# DISPC register map
Vendor: Texas Instruments
Registers are 32-bit, access per field, reset 0x0 unless marked. A register's access mark holds for its fields unless they carry their own. Offsets are as the file gives them; [hi:lo] are bit positions; {n}, {i} and the like mark numbered series; 'fields as' and 'values as' point back to an identical list.

## DISPC (part 5 of 7)
0x3A4 DISPC_VID3_ROW_INC rw reset 0x1 — The register configures the number of bytes to increment at the end of the row for the buffer associated with the video window 3. Shadow register, updated on VFP start period of primary LCD or VFP start period of the secondary LCD or VFP start period of the third LCD or EVSYNC or when.GOWB is set to 1 by software and current WB frame is finished (no more data in the write-back pipeline). The synchronization event is defined based on the output using the pipeline: primary LCD, secondary LCD, third LCD, TV output or write-back to the memory
  [31:0] ROWINC — Number of bytes to increment at the end of the row Encoded signed value (from 21 to 2) to specify the number of bytes to increment at the end of the row in the video buffer. The value 0 is invalid. The value 1 means next pixel. The value 1 + n * bpp means increment of n pixels. The value 1 (n + 1) * bpp means decrement of n pixels.
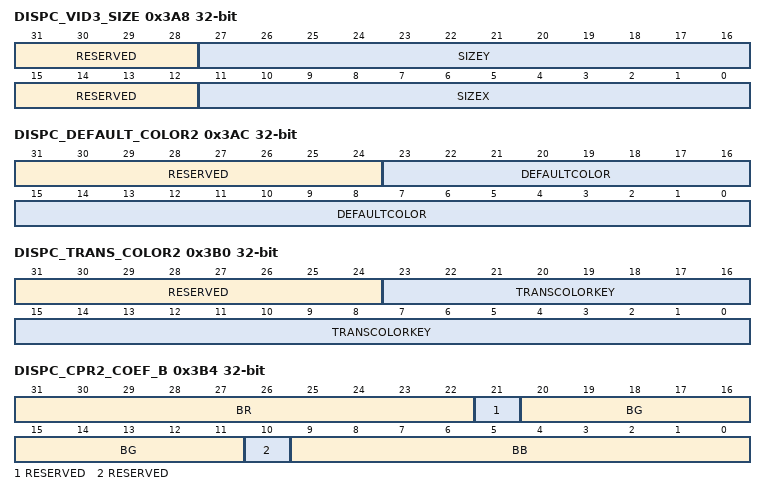
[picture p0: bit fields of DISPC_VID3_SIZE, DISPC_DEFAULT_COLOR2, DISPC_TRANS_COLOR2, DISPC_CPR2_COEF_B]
0x3A8 DISPC_VID3_SIZE — The register configures the size of the video window 3. Shadow register, updated on VFP start period of primary LCD or VFP start period of the secondary LCD or VFP start period of the third LCD or EVSYNC or when.GOWB is set to 1 by software and current WB frame is finished (no more data in the write-back pipeline). The synchronization event is defined based on the output using the pipeline: primary LCD, secondary LCD, third LCD, TV output or write-back to the memory
  [31:28] RESERVED ro — Write 0s for future compatibility. Reads return 0.
  [27:16] SIZEY rw — Number of lines of the video 3 Encoded value (from 1 to 4096) to specify the number of lines of the video window 3. Program to value minus 1.
  [15:12] RESERVED ro — Write 0s for future compatibility. Reads return 0.
  [11:0] SIZEX rw — Number of pixels of the video window 3 Encoded value (from 1 to 4096) to specify the number of pixels of the video window 3. Program to value minus 1.
0x3AC DISPC_DEFAULT_COLOR2 — The control register allows to configure the default solid background color for the secondary LCD Shadow register, updated on VFP start period of secondary LCD
  [31:24] RESERVED ro — Write 0s for future compatibility. Reads return 0.
  [23:0] DEFAULTCOLOR rw — 24-bit RGB color value to specify the default solid color to display when there is no data from the overlays.
0x3B0 DISPC_TRANS_COLOR2 — The register sets the transparency color value for the video/graphics overlays for the secondary LCD output. Shadow register, updated on VFP start period of the secondary LCD
  [31:24] RESERVED ro — Write 0s for future compatibility. Reads return 0.
  [23:0] TRANSCOLORKEY rw — Transparency Color Key Value in RGB format [0] BITMAP 1 (CLUT), [23,1] set to 0s [1:0] BITMAP 2 (CLUT), [23,2] set to 0s [3:0] BITMAP 4 (CLUT), [23,4] set to 0s [7:0] BITMAP 8 (CLUT), [23,8] set to 0s [11:0] RGB 12, [23,12] set to 0s [15:0] RGB 16, [23,16] set to 0s [23:0] RGB 24
0x3B4 DISPC_CPR2_COEF_B — The register configures the color phase rotation matrix coefficients for the Blue component. It is used for the secondary LCD output. Shadow register, updated on VFP start period of secondary LCD
  [31:22] BR rw — BR coefficient encoded signed value (from –512 to 511).
  [21] RESERVED ro — Write 0s for future compatibility. Reads return 0.
  [20:11] BG rw — BG coefficient encoded signed value (from –512 to 511).
  [10] RESERVED ro — Write 0s for future compatibility. Reads return 0.
  [9:0] BB rw — BB coefficient encoded signed value (from –512 to 511).
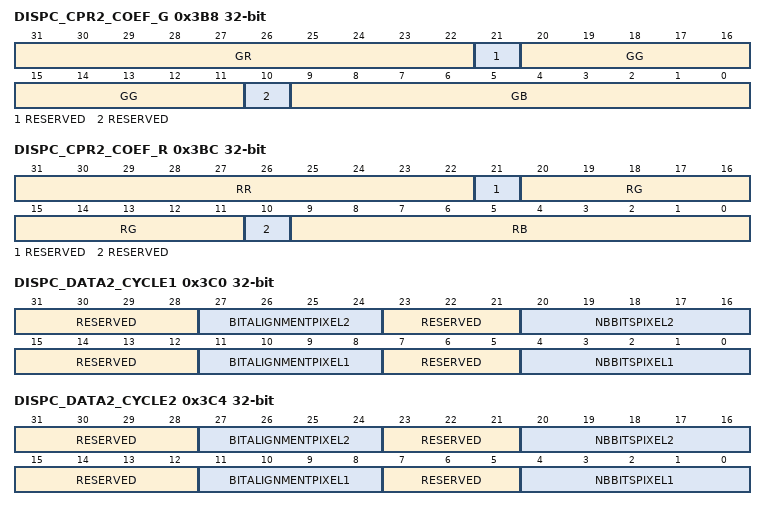
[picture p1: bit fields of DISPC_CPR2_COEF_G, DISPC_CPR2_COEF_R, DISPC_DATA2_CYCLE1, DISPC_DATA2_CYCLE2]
0x3B8 DISPC_CPR2_COEF_G — The register configures the color phase rotation matrix coefficients for the Green component. It is used for the secondary LCD output. Shadow register, updated on VFP start period of secondary LCD
  [31:22] GR rw — GR coefficient encoded signed value (from –512 to 511).
  [21] RESERVED ro — Write 0s for future compatibility. Reads return 0.
  [20:11] GG rw — GG coefficient encoded signed value (from –512 to 511).
  [10] RESERVED ro — Write 0s for future compatibility. Reads return 0.
  [9:0] GB rw — GB coefficient encoded signed value (from –512 to 511).
0x3BC DISPC_CPR2_COEF_R — The register configures the color phase rotation matrix coefficients for the Red component. Shadow register, updated on VFP start period of secondary LCD
  [31:22] RR rw — RR coefficient encoded signed value (from –512 to 511).
  [21] RESERVED ro — Write 0s for future compatibility. Reads return 0.
  [20:11] RG rw — RG coefficient encoded signed value (from –512 to 511).
  [10] RESERVED ro — Write 0s for future compatibility. Reads return 0.
  [9:0] RB rw — RB coefficient encoded signed value (from –512 to 511).
0x3C0 DISPC_DATA2_CYCLE1 — The control register configures the output data format for 1st cycle. Shadow register, updated on VFP start period of secondary LCD
  [31:28] RESERVED ro — Write 0s for future compatibility. Reads return 0.
  [27:24] BITALIGNMENTPIXEL2 rw — Bit alignment. Alignment of the bits from pixel 2 on the output interface
  [23:21] RESERVED ro — Write 0s for future compatibility. Reads return 0.
  [20:16] NBBITSPIXEL2 rw — Number of bits Number of bits from the pixel 2 (value from 0 to 16 bits). The values from 17 to 31 are invalid.
  [15:12] RESERVED ro — Write 0s for future compatibility. Reads return 0.
  [11:8] BITALIGNMENTPIXEL1 rw — Bit alignment. Alignment of the bits from pixel 1 on the output interface
  [7:5] RESERVED ro — Write 0s for future compatibility. Reads return 0.
  [4:0] NBBITSPIXEL1 rw — Number of bits Number of bits from the pixel 1 (value from 0 to 16 bits). The values from 17 to 31 are invalid.
0x3C4 DISPC_DATA2_CYCLE2 — The control register configures the output data format for 2nd cycle. Shadow register, updated on VFP start period of secondary LCD
  [31:28] RESERVED ro — Write 0s for future compatibility Reads return 0.
  [27:24] BITALIGNMENTPIXEL2 rw — Bit alignment. Alignment of the bits from pixel 2 on the output interface
  [23:21] RESERVED ro — Write 0s for future compatibility Reads return 0.
  [20:16] NBBITSPIXEL2 rw — Number of bits Number of bits from the pixel 2 (value from 0 to 16 bits). The values from 17 to 31 are invalid.
  [15:12] RESERVED ro — Write 0s for future compatibility Reads return 0.
  [11:8] BITALIGNMENTPIXEL1 rw — Bit alignment. Alignment of the bits from pixel 1 on the output interface
  [7:5] RESERVED ro — Write 0s for future compatibility Reads return 0.
  [4:0] NBBITSPIXEL1 rw — Number of bits Number of bits from the pixel 1 (value from 0 to 16 bits). The values from 17 to 31 are invalid.
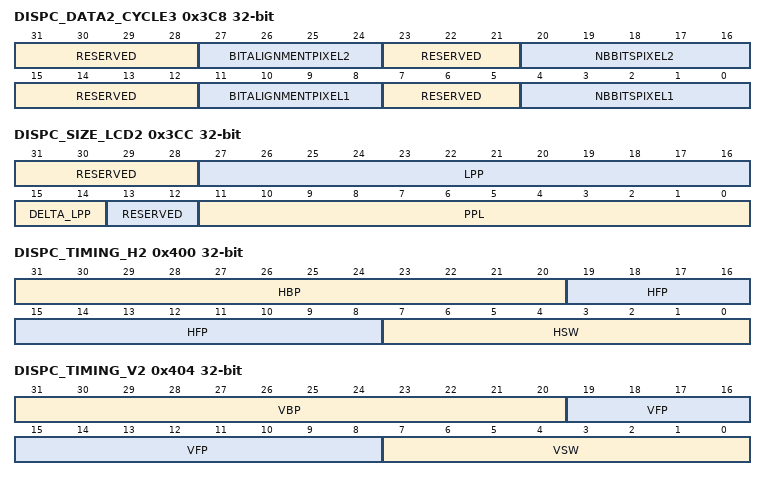
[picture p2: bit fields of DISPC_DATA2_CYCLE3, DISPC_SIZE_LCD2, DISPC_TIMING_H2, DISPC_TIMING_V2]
0x3C8 DISPC_DATA2_CYCLE3 — The control register configures the output data format for 3rd cycle. Shadow register, updated on VFP start period of secondary LCD
  fields as DISPC_DATA2_CYCLE2
0x3CC DISPC_SIZE_LCD2 — The register configures the panel size (horizontal and vertical). It is used for the secondary LCD output. Shadow register, updated on VFP start period of secondary LCD. A delta value is used to indicate if the odd field has same vertical size as the even field or +/- one line.
  [31:28] RESERVED ro — Write 0s for future compatibility. Reads return 0.
  [27:16] LPP rw — Lines per panel encoded value (from 1 to 4096) to specify the number of lines per panel (program to value minus 1).
  [15:14] DELTA_LPP rw — Indicates the delta size value of the odd field compared to the even field
    0=same size; 1=PlusOne (odd size = even size +1); 2=MinusOne (Odd size = even size –1)
  [13:12] RESERVED ro — Write 0s for future compatibility. Reads return 0.
  [11:0] PPL rw — Pixels per line encoded value (from 1 to 4096) to specify the number of pixels contains within each line on the display (program to value minus 1). In STALL mode, any value is valid. In non STALL mode, only values multiple of 8 pixels are valid.
0x400 DISPC_TIMING_H2 rw — The register configures the timing logic for the HSYNC signal. It is used for the secondary LCD output. Shadow register, updated on VFP start period of secondary LCD
  [31:20] HBP — Horizontal back porch. Encoded value (from 1 to 4096) to specify the number of pixel clock periods to add to the beginning of a line transmission before the first set of pixels is output to the display (program to value minus 1).
  [19:8] HFP — Horizontal front porch. Encoded value (from 1 to 4096) to specify the number of pixel clock periods to add to the end of a line transmission before line clock is asserted (program to value minus 1).
  [7:0] HSW — Horizontal synchronization pulse width encoded value (from 1 to 256) to specify the number of pixel clock periods to pulse the line clock at the end of each line (program to value minus 1).
0x404 DISPC_TIMING_V2 rw — The register configures the timing logic for the VSYNC signal. It is used for the secondary LCD output. Shadow register, updated on VFP start period of secondary LCD
  [31:20] VBP — Vertical back porch encoded value (from 0 to 4095) to specify the number of line clock periods to add to the beginning of a frame before the first set of pixels is output to the display.
  [19:8] VFP — Vertical front porch encoded value (from 0 to 4095) to specify the number of line clock periods to add to the end of each frame.
  [7:0] VSW — Vertical synchronization pulse width In active mode, encoded value (from 1 to 256) to specify the number of line clock periods (program to value minus 1) to pulse the frame clock (VSYNC) pin at the end of each frame after the end of frame wait (VFP) period elapses. Frame clock uses as VSYNC signal in active mode.
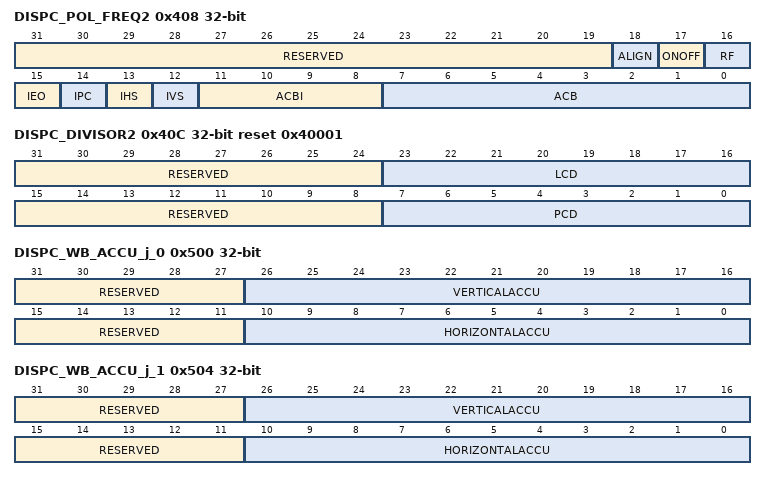
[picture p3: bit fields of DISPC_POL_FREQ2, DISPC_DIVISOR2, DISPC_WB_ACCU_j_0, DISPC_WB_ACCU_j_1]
0x408 DISPC_POL_FREQ2 — The register configures the signal configuration. It is used for the secondary LCD output. Shadow register, updated on VFP start period of secondary LCD
  [31:19] RESERVED ro — Write 0s for future compatibility. Reads return 0.
  [18] ALIGN rw — Defines the alignment between HSYNC and VSYNC assertion.
    0=notAligned (VSYNC and HSYNC are not aligned.); 1=Aligned (VSYNC and HSYNC assertions are aligned.)
  [17] ONOFF rw — HSYNC/VSYNC Pixel clock Control On/Off
    0=DOpEdPCk (HSYNC and VSYNC are driven on opposite edges of pixel clock than pixel data.); 1=DBit16 (HSYNC and VSYNC are driven according to bit 16.)
  [16] RF rw — Program HSYNC/VSYNC Rise or Fall
    0=DFEdPCk (HSYNC and VSYNC are driven on falling edge of pixel clock (if bit 17 set to 1).); 1=DRiEdPCk (HSYNC and VSYNC are driven on rising edge of pixel clock (if bit 17 set to 1).)
  [15] IEO rw — Invert output enable
    0=ACBaHigh (Ac-bias is active high (active display mode).); 1=ACBaLow (Ac-bias is active low (active display mode).)
  [14] IPC rw — Invert pixel clock
    0=DrPCk (Data is driven on the LCD data lines on the rising-edge of the pixel clock.); 1=DfPCk (Data is driven on the LCD data lines on the falling-edge of the pixel clock.)
  [13] IHS rw — Invert HSYNC
    0=LCkpinAh (Line clock pin is active high and inactive low.); 1=LCkpinAl (Line clock pin is active low and inactive high.)
  [12] IVS rw — Invert VSYNC
    0=FCkpinAh (Frame clock pin is active high and inactive low.); 1=FCkpinAl (Frame clock pin is active low and inactive high.)
  [11:8] ACBI rw — AC Bias Pin transitions per interrupt Value (from 0 to 15) used to specify the number of AC Bias pin transitions
  [7:0] ACB rw — AC Bias Pin Frequency Value (from 0 to 255) used to specify the number of line clocks to count before transitioning the AC Bias pin. This pin is used to periodically invert the polarity of the power supply to prevent DC charge build-up within the display.
0x40C DISPC_DIVISOR2 reset 0x40001 — The register configures the divisors. It is used for the secondary LCD output. Shadow register, updated on VFP start period of secondary LCD
  [31:24] RESERVED ro — Write 0s for future compatibility. Reads return 0.
  [23:16] LCD rw — Display controller logic clock divisor value (from 1 to 255) to specify the intermediate pixel clock frequency based on the LCD2_CLK. The value 0 is invalid.
  [15:8] RESERVED ro — Write 0s for future compatibility. Reads return 0.
  [7:0] PCD rw — Pixel clock divisor value (from 1 to 255) to specify the frequency of the pixel clock based on the LCD2_CLK divided byDISPC_DIVISOR2.LCD value. The value 0 is invalid.
0x500 DISPC_WB_ACCU_j_0 — The register configures the resize accumulator init values for horizontal and vertical up/downsampling of the write back pipeline (DISPC_WB_ACCU_0 and DISPC_WB_ACCU_1 for ping-pong mechanism with external trigger, based on the field polarity). It is used for ARGB and Y setting. Shadow register, updated when.GOWB is set to 1 by software and current WB frame is finished (no more data in the write-back pipeline) when the WB pipeline is directly connected to one of the pipelines (graphics or video), otherwise updated on VFP start period of primary LCD or VFP start period of secondary LCD or VFP start period of the third LCD or EVSYNC depending on which overlay output is selected as an input to the WB pipeline
  [31:27] RESERVED ro — Write 0s for future compatibility. Reads return 0.
  [26:16] VERTICALACCU rw — Vertical initialization accumulator value Encoded value (from –1024 to 1023).
  [15:11] RESERVED ro — Write 0s for future compatibility. Reads return 0.
  [10:0] HORIZONTALACCU rw — Horizontal initialization accumulator value encoded value (from –1024 to 1023).
0x504 DISPC_WB_ACCU_j_1 — The register configures the resize accumulator init values for horizontal and vertical up/downsampling of the write back pipeline (DISPC_WB_ACCU_0 and DISPC_WB_ACCU_1 for ping-pong mechanism with external trigger, based on the field polarity). It is used for ARGB and Y setting. Shadow register, updated when.GOWB is set to 1 by software and current WB frame is finished (no more data in the write-back pipeline) when the WB pipeline is directly connected to one of the pipelines (graphics or video), otherwise updated on VFP start period of primary LCD or VFP start period of secondary LCD or VFP start period of the third LCD or EVSYNC depending on which overlay output is selected as an input to the WB pipeline
  fields as DISPC_WB_ACCU_j_0
0x508 DISPC_WB_BA_j_0 rw — The register configures the base address of the WB buffer (DISPC_WB_BA_0 and DISPC_WB_BA_1 for ping-pong mechanism with external trigger, based on the field polarity otherwise only DISPC_WB_BA_0 is used). Shadow register, updated when.GOWB is set to 1 by software and current WB frame is finished (no more data in the write-back pipeline) when the WB pipeline is directly connected to one of the pipelines (graphics or video), otherwise updated on VFP start period of primary LCD or VFP start period of secondary LCD or VFP start period of the third LCD or EVSYNC depending on which overlay output is selected as an input to the WB pipeline
  [31:0] BA — Write-back base address Base address of the WB buffer (aligned on pixel size boundary except in case of RGB24 packed format, 4-pixel alignment is required; in case of YUV4:2:2, 2-pixel alignment is required, and YUV4:2;0, byte alignment is supported)). It case of YUV4:2:0 format, it indicates the base address of the Y buffer. When the TILER is addressed, the bits: [28:27] = 0x0 for 8-bit tiled [28:27] = 0x1 for 16-bit tiled [28:27] = 0x2 for 32-bit tiled [28:27] = 0x3 for page mode [31:29] = 0x0 for 0-degree view [31:29] = 0x1 for 180-degree view + mirroring [31:29] = 0x2 for 0-degree view + mirroring [31:29] = 0x3 for 180-degree view [31:29] = 0x4 for 270-degree view + mirroring [31:29] = 0x5 for 270-degree view [31:29] = 0x6 for 90-degree view [31:29] = 0x7 for 90-degree view + mirroring Otherwise the bits indicated the corresponding bit address to access the SDRAM.
0x50C DISPC_WB_BA_j_1 rw — The register configures the base address of the WB buffer (DISPC_WB_BA_0 and DISPC_WB_BA_1 for ping-pong mechanism with external trigger, based on the field polarity otherwise only DISPC_WB_BA_0 is used). Shadow register, updated when.GOWB is set to 1 by software and current WB frame is finished (no more data in the write-back pipeline) when the WB pipeline is directly connected to one of the pipelines (graphics or video), otherwise updated on VFP start period of primary LCD or VFP start period of secondary LCD or VFP start period of the third LCD or EVSYNC depending on which overlay output is selected as an input to the WB pipeline
  fields as DISPC_WB_BA_j_0
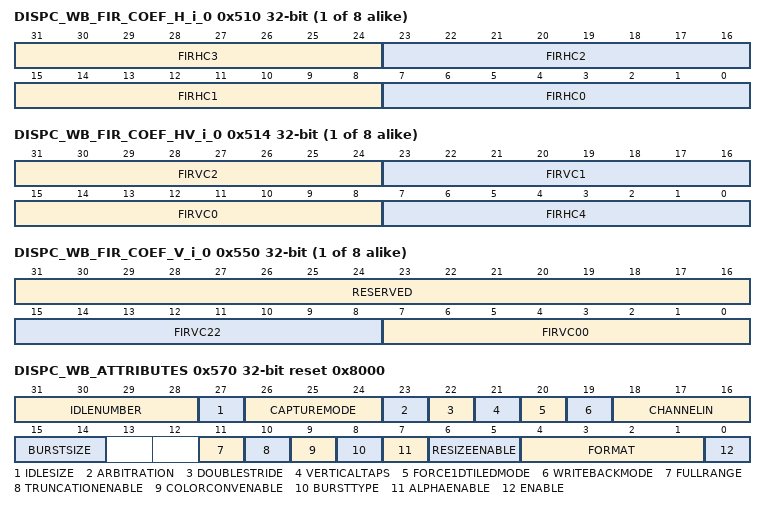
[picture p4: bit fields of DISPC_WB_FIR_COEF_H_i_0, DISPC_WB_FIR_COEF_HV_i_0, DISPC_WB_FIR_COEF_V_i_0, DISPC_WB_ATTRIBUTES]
{0x510+8i} DISPC_WB_FIR_COEF_H_i_{i} rw (i=0..7) — The bank of registers configure the up/down-scaling coefficients for the horizontal resize of the video picture associated with the write back pipeline for the phases from 0 to 7. It is used for ARGB and Y setting. Shadow register, updated when.GOWB is set to 1 by software and current WB frame is finished (no more data in the write-back pipeline) when the WB pipeline is directly connected to one of the pipelines (graphics or video), otherwise updated on VFP start period of primary LCD or VFP start period of secondary LCD or VFP start period of the third LCD or EVSYNC depending on which overlay output is selected as an input to the WB pipeline
  [31:24] FIRHC3 — Signed coefficient C3 for the horizontal up/down-scaling with the phase n
  [23:16] FIRHC2 — Unsigned coefficient C2 for the horizontal up/down-scaling with the phase n
  [15:8] FIRHC1 — Signed coefficient C1 for the horizontal up/down-scaling with the phase n
  [7:0] FIRHC0 — Signed coefficient C0 for the horizontal up/down-scaling with the phase n
{0x514+8i} DISPC_WB_FIR_COEF_HV_i_{i} rw (i=0..7) — The bank of registers configure the down/up/down-scaling coefficients for the vertical and horizontal resize of the video picture associated with the write back pipeline for the phases from 0 to 7. It is used for ARGB and Y setting. Shadow register, updated when.GOWB is set to 1 by software and current WB frame is finished (no more data in the write-back pipeline) when the WB pipeline is directly connected to one of the pipelines (graphics or video), otherwise updated on VFP start period of primary LCD or VFP start period of secondary LCD or VFP start period of the third LCD or EVSYNC depending on which overlay output is selected as an input to the WB pipeline
  [31:24] FIRVC2 — Signed coefficient C2 for the vertical up/down-scaling with the phase n
  [23:16] FIRVC1 — Unsigned coefficient C1 for the vertical up/down-scaling with the phase n
  [15:8] FIRVC0 — Signed coefficient C0 for the vertical up/down-scaling with the phase n
  [7:0] FIRHC4 — Signed coefficient C4 for the horizontal up/down-scaling with the phase n
{0x550+4i} DISPC_WB_FIR_COEF_V_i_{i} (i=0..7) — The bank of registers configure the down/up/down-scaling coefficients for the vertical resize of the video picture associated with the write back pipeline for the phases from 0 to 7. It is used for ARGB and Y setting. Shadow register, updated on VFP start period of primary LCD or VFP start period of the secondary LCD or VFP start period of the third LCD or EVSYNC or when.GOWB is set to 1 by software and current WB frame is finished (no more data in the write-back pipeline). The synchronization event is defined based on the output using the pipeline: primary LCD, secondary LCD, third LCD, TV output or write-back to the memory
  [31:16] RESERVED ro — Write 0s for future compatibility. Reads return 0.
  [15:8] FIRVC22 rw — Signed coefficient C22 for the vertical up/down-scaling with the phase n
  [7:0] FIRVC00 rw — Signed coefficient C00 for the vertical up/down-scaling with the phase n
0x570 DISPC_WB_ATTRIBUTES rw reset 0x8000 — The register configures the attributes of the viwrite back pipeline. Shadow register, updated when.GOWB is set to 1 by software and current WB frame is finished (no more data in the write-back pipeline) when the WB pipeline is directly connected to one of the pipelines (graphics or video), otherwise updated on VFP start period of primary LCD or VFP start period of secondary LCD or VFP start period of the third LCD or EVSYNC depending on which overlay output is selected as an input to the WB pipeline
  [31:28] IDLENUMBER — Determines the number of idles between requests on the L3_MAIN interconnect. It is only used when the write-back pipeline does data transfer from memory to memory. When the output of an overlay is stored in memory through the write-back pipeline in capture mode, the bit field IDLENUMBER is ignored since a timing generator is used to time the transfer. The number of IDLE cycles is IDLENUMBER (from 0 to 15) if IDLESIZE = 0. The number of IDLE cycles is IDLENUMBERx8 (from 0 to 120) if IDLESIZE = 1 and BURSTSIZE = 2. The number of IDLE cycles is IDLENUMBERx4 (from 0 to 60) if IDLESIZE = 1 and BURSTSIZE = 1. The number of IDLE cycles is IDLENUMBERx2 (from 0 to 30) if IDLESIZE = 1 and BURSTSIZE = 0.
  [27] IDLESIZE — Determines if the IDLENUMBER corresponds to a number of bursts or singles.
    0=IdleSingle (The number of idles between requests is defined by IDLENUMBER as number of cycles.); 1=IdleBurst (The number of idles between requests is defined by IDLENUMBER multiplied by burst size as number of cycles.)
  [26:24] CAPTUREMODE — Defines the frame rate capture.
    6=Only1_6 (Only one out of six frames is captured. The first one is captured then the second one is skipped and so on.); 1=Only1 (Only one frame is captured.); 7=Only1_7 (Only one out of seven frames is captured. The first one is captured then the second one is skipped and so on.); 0=All (All frames are captures until the write-back channel is disabled or there is no more data generated by the overlay or the pipeline attached to the write-back channel.); 2=Only1_2 (Only one out of two frames is captured. The first one is captured, and then the second one is skipped, and so on.); 4=Only1_4 (Only one out of four frames is captured. The first one is captured, and then the second one is skipped, and so on.); 5=Only1_5 (Only one out of five frames is captured. The first one is captured, and then the second one is skipped, and so on.); 3=Only1_3 (Only one out of three frames is captured. The first one is captured, and then the second one is skipped, and so on.)
  [23] ARBITRATION — Determines the priority of the write-back pipeline. The write-back pipeline is one of the high priority pipeline. The arbitration gives always the priority first to the high priority pipelines using round-robin between them. When there is only normal priority pipelines sending requests, the round-robin applies between them.
    0=NormalPrio (The write-back pipeline is one of the normal priority pipeline.); 1=HighPrio (The write-back pipeline is one of the high priority pipeline.)
  [22] DOUBLESTRIDE — Determines if the stride for CbCr buffer is the 1x or 2x of the Y buffer stride. It is only used in case of YUV4:2:0.
    0=Initial (The CbCr stride value is equal to the Y stride.); 1=Double (The CbCr stride value is double to the Y stride.)
  [21] VERTICALTAPS — Video Vertical Resize Tap Number
    0=taps3 (3 taps are used for the vertical filtering logic. The 2 other taps are not used.); 1=taps5 (5 taps are used for the vertical filtering logic.)
  [20] FORCE1DTILEDMODE — Force TILED regions access to 1D or 2D.
    0=TiledRegions2DAccess (2D accesses for tiled regions); 1=TiledRegions1DAccess (1D accesses for tiled regions)
  [19] WRITEBACKMODE — When connected to the overlay output of a channel the write back can operate as a simple transfer from memory to memory (composition engine) or as a capture channel. 0x0: Capture mode (default mode) 0x1: Memory-to-memory mode
  [18:16] CHANNELIN — Video Channel In configuration WR: immediate
    6=Vid3 (Video3 pipeline output); 1=LCD2 (Secondary LCD output); 0=LCD1 (Primary LCD overlay output); 2=TV (TV overlay output); 4=Vid1 (Video1 pipeline output); 5=Vid2 (Video2 pipeline output); 3=Gfx (Graphics pipeline output); 7=LCD3 (Third LCD output)
  [15:14] BURSTSIZE — Write-back DMA Burst Size
    0=Burst2x128b (2 × 128-bit bursts); 1=Burst4x128b (4 × 128-bit bursts); 2=Burst8x128b (8 × 128-bit bursts)
  [11] FULLRANGE — Color Space Conversion full range setting.
    0=Limrange (Limited range selected: 16 subtracted from Y before color space conversion); 1=Full range selected: Y is not modified before the color space conversion
  [10] TRUNCATIONENABLE — It applies only when the input format to the write-back pipeline from the overlay or directly from one of the pipelines is ARGB32. If the format is one of the YUV supported formats, the bit field is ignored.
    0=WBTruncDis (Disable truncation logic); 1=WBTruncEnb (Enable truncation logic from ARGB32 to the pixel format defined in the field FORMAT.)
  [9] COLORCONVENABLE — Enable the color space conversion. The hardware does not enable/disable the conversion based on the pixel format. The bit field shall be reset when the format is not YUV.
    0=ColSpCDis (Disable Color Space Conversion RGB to YUV); 1=ColSpCEnb (Enable Color Space Conversion RGB to YUV)
  [8] BURSTTYPE — The type of burst can be INCR (incremental) or BLCK (2D block). The 2D block is required when the TILER is targeted by the DMA engine.
    0=1D_burst (INC burst type is used.); 1=2D_burst (2D block burst type is used.)
  [7] ALPHAENABLE — Premultiplied alpha enable Read 0x1: Enabled Read 0x0: Disabled. This bit also disable the logic present in the associated channel out that compute the alpha component sent to the WB pipe. When the WB is configured to copy back one of the output channels (output of overlay), the following configurations are available: 0x1: The WB pipe copies back to memory the premultiplied alpha calculated through the overlay. 0x0: The alpha value is not written back.
  [6:5] RESIZEENABLE
    0=ReSizeProc (Disable the resize processing); 1=HReSize (Enable the horizontal resize processing); 3=HVReSize (Enable both horizontal and vertical resize processing); 2=VReSize (Enable the vertical resize processing)
  [4:1] FORMAT — Write-back format. It defines the pixel format when storing the write-back picture into memory.
    6=RGB16 (RGB16-565); 1=RGBx12 (RGB12x-4444); 10=YUV2 (YUV2 4:2:2 co-sited); 7=ARGB16_1 (ARGB16-1555); 13=RGBA32 (RGBA32-8888); 0=NV12 (NV12 4:2:0 2 buffers (Y + UV)); 2=RGBA12 (RGBA12-4444); 8=xRGB24-8888 (32-bit container); 9=RGB24 (RGB24-888 (24-bit container)); 11=UYVY (UYVY 4:2:2 co-sited); 5=ARGB16 (ARGB16-4444); 15=xRGB15-1555; 12=ARGB32 (ARGB32-8888); 4=xRGB12-4444; 3=BGRA32 (BGRA32-8888); 14=xRGB12 (RGBx24-8888 (24-bit RGB aligned on MSB of the 32-bit container))
  [0] ENABLE — Write-back enable. wr: immediate
    0=WBDis (Write-back disabled); 1=WBEnb (Write-back enabled)
